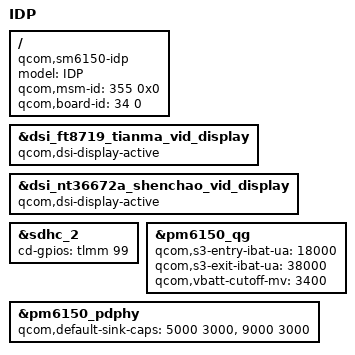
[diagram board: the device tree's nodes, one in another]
/* Copyright (c) 2018, The Linux Foundation. All rights reserved.
 *
 * This program is free software; you can redistribute it and/or modify
 * it under the terms of the GNU General Public License version 2 and
 * only version 2 as published by the Free Software Foundation.
 *
 * This program is distributed in the hope that it will be useful,
 * but WITHOUT ANY WARRANTY; without even the implied warranty of
 * MERCHANTABILITY or FITNESS FOR A PARTICULAR PURPOSE.  See the
 * GNU General Public License for more details.
 */

/dts-v1/;
/plugin/;

#include <dt-bindings/interrupt-controller/arm-gic.h>
#include <dt-bindings/clock/qcom,camcc-sm6150.h>

#include "sm6150-idp.dtsi"
#include "sm6150-audio-overlay.dtsi"

/ {
	model = "IDP";
	compatible = "qcom,sm6150-idp", "qcom,sm6150", "qcom,idp";
	qcom,msm-id = <355 0x0>;
	qcom,board-id = <34 0>;
};

&dsi_ft8719_tianma_vid_display {
	qcom,dsi-display-active;
};

&dsi_nt36672a_shenchao_vid_display {
	qcom,dsi-display-active;
};

&sdhc_2 {
	cd-gpios = <&tlmm 99 0>;
};

&pm6150_qg {
	qcom,s3-entry-ibat-ua = <18000>;
	qcom,s3-exit-ibat-ua = <38000>;
	qcom,vbatt-cutoff-mv = <3400>;
};

&pm6150_pdphy{
	qcom,default-sink-caps = <5000 3000>, /* 5V @ 3A */
						 <9000 3000>; /* 9V @ 3A */
};
